VERSION ""

NS_ :

BS_:

BU_: Main_Module Torque_Vector Driveline Precharge Dashboard BMS_LV TESTER Precharge BMS1 TEST_NODE TEST_NODE_2 DAQ

BO_ 2214592576 driver_request: 4 Main_Module
 SG_ regen : 16|16@1+ (1,0) [0|0] "" Vector__XXX
 SG_ accel : 0|16@1+ (1,0) [0|0] "" Vector__XXX

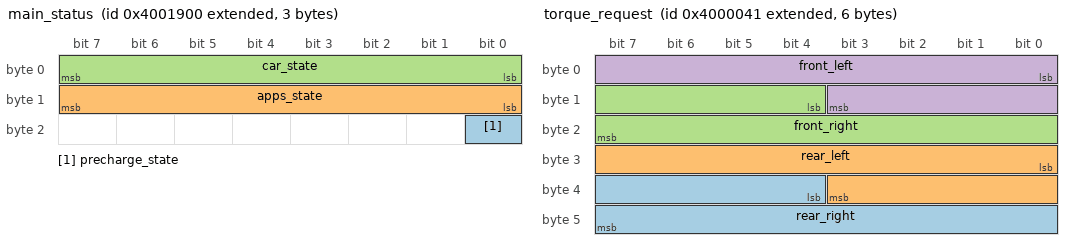
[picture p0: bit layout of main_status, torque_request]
BO_ 2214598912 main_status: 3 Main_Module
 SG_ precharge_state : 16|1@1+ (1,0) [0|0] "" Vector__XXX
 SG_ apps_state : 8|8@1+ (1,0) [0|0] "" Vector__XXX
 SG_ car_state : 0|8@1+ (1,0) [0|0] "" Vector__XXX

BO_ 2214592577 torque_request: 6 Torque_Vector
 SG_ rear_right : 36|12@1+ (1,0) [0|0] "" Vector__XXX
 SG_ rear_left : 24|12@1+ (1,0) [0|0] "" Vector__XXX
 SG_ front_right : 12|12@1+ (1,0) [0|0] "" Vector__XXX
 SG_ front_left : 0|12@1+ (1,0) [0|0] "" Vector__XXX

BO_ 2147490049 bitstream_flash_status: 1 Torque_Vector
 SG_ flash_timeout_rx : 1|1@1+ (1,0) [0|0] "" Vector__XXX
 SG_ flash_success : 0|1@1+ (1,0) [0|0] "" Vector__XXX

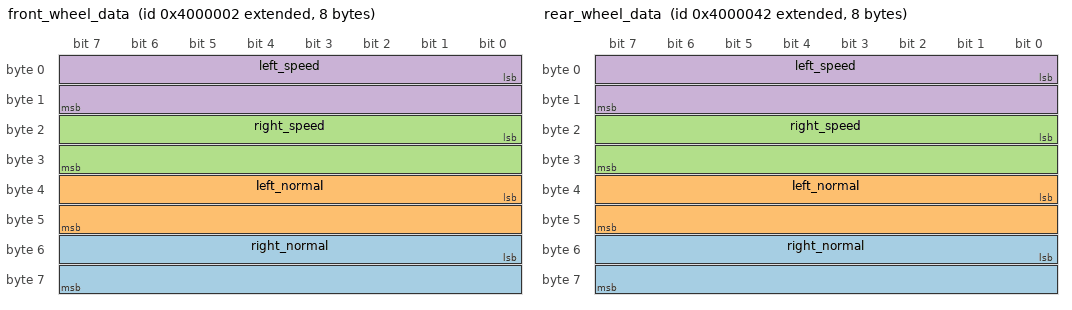
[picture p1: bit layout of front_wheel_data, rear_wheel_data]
BO_ 2214592514 front_wheel_data: 8 Driveline
 SG_ right_normal : 48|16@1+ (1,0) [0|0] "" Vector__XXX
 SG_ left_normal : 32|16@1+ (1,0) [0|0] "" Vector__XXX
 SG_ right_speed : 16|16@1+ (1,0) [0|0] "" Vector__XXX
 SG_ left_speed : 0|16@1+ (1,0) [0|0] "" Vector__XXX

BO_ 2214592578 rear_wheel_data: 8 Driveline
 SG_ right_normal : 48|16@1+ (1,0) [0|0] "" Vector__XXX
 SG_ left_normal : 32|16@1+ (1,0) [0|0] "" Vector__XXX
 SG_ right_speed : 16|16@1+ (1,0) [0|0] "" Vector__XXX
 SG_ left_speed : 0|16@1+ (1,0) [0|0] "" Vector__XXX

BO_ 2348810882 front_motor_currents: 4 Driveline
 SG_ right : 16|16@1+ (1,0) [0|0] "" Vector__XXX
 SG_ left : 0|16@1+ (1,0) [0|0] "" Vector__XXX

BO_ 2348810946 rear_motor_currents: 4 Driveline
 SG_ right : 16|16@1+ (1,0) [0|0] "" Vector__XXX
 SG_ left : 0|16@1+ (1,0) [0|0] "" Vector__XXX

BO_ 2281734148 test_precharge_msg: 1 Precharge
 SG_ test_precharge_sig : 0|8@1+ (1,0) [0|0] "" Vector__XXX

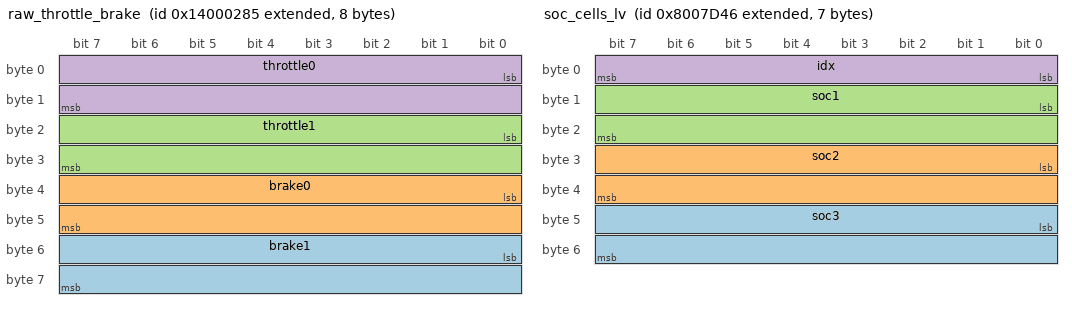
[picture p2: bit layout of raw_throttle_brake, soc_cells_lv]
BO_ 2483028613 raw_throttle_brake: 8 Dashboard
 SG_ brake1 : 48|16@1+ (1,0) [0|0] "" Vector__XXX
 SG_ brake0 : 32|16@1+ (1,0) [0|0] "" Vector__XXX
 SG_ throttle1 : 16|16@1+ (1,0) [0|0] "" Vector__XXX
 SG_ throttle0 : 0|16@1+ (1,0) [0|0] "" Vector__XXX

BO_ 2214592517 start_button: 1 Dashboard
 SG_ start : 0|1@1+ (1,0) [0|0] "" Vector__XXX

BO_ 2281733446 soc_cells_lv: 7 BMS_LV
 SG_ soc3 : 40|16@1+ (1,0) [0|0] "" Vector__XXX
 SG_ soc2 : 24|16@1+ (1,0) [0|0] "" Vector__XXX
 SG_ soc1 : 8|16@1+ (1,0) [0|0] "" Vector__XXX
 SG_ idx : 0|8@1+ (1,0) [0|0] "" Vector__XXX

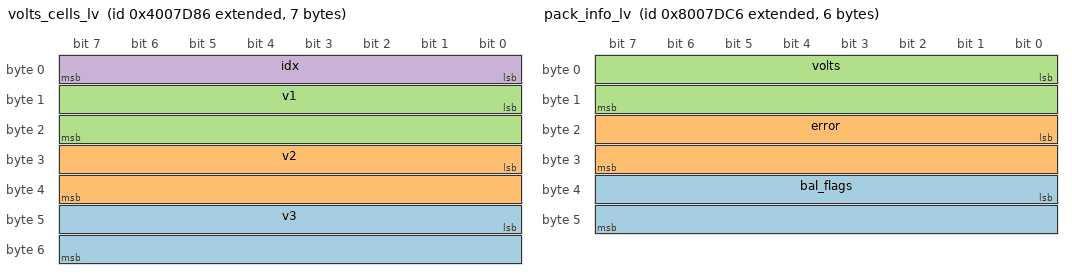
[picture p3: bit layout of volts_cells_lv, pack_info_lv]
BO_ 2214624646 volts_cells_lv: 7 BMS_LV
 SG_ v3 : 40|16@1+ (1,0) [0|0] "" Vector__XXX
 SG_ v2 : 24|16@1+ (1,0) [0|0] "" Vector__XXX
 SG_ v1 : 8|16@1+ (1,0) [0|0] "" Vector__XXX
 SG_ idx : 0|8@1+ (1,0) [0|0] "" Vector__XXX

BO_ 2281733574 pack_info_lv: 6 BMS_LV
 SG_ bal_flags : 32|16@1+ (1,0) [0|0] "" Vector__XXX
 SG_ error : 16|16@1+ (1,0) [0|0] "" Vector__XXX
 SG_ volts : 0|16@1+ (1,0) [0|0] "" Vector__XXX

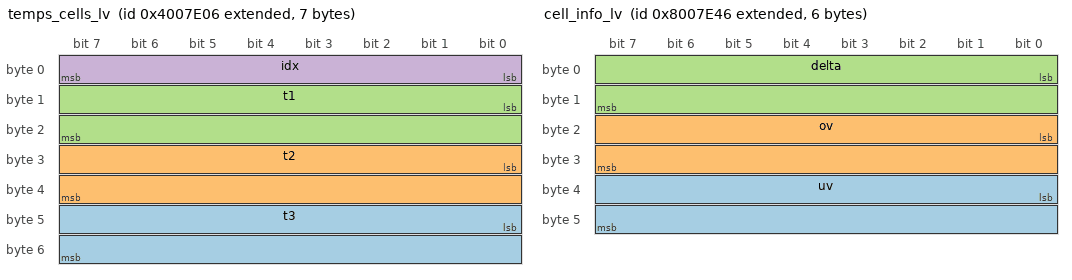
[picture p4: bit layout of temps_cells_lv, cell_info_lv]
BO_ 2214624774 temps_cells_lv: 7 BMS_LV
 SG_ t3 : 40|16@1+ (1,0) [0|0] "" Vector__XXX
 SG_ t2 : 24|16@1+ (1,0) [0|0] "" Vector__XXX
 SG_ t1 : 8|16@1+ (1,0) [0|0] "" Vector__XXX
 SG_ idx : 0|8@1+ (1,0) [0|0] "" Vector__XXX

BO_ 2281733702 cell_info_lv: 6 BMS_LV
 SG_ uv : 32|16@1+ (1,0) [0|0] "" Vector__XXX
 SG_ ov : 16|16@1+ (1,0) [0|0] "" Vector__XXX
 SG_ delta : 0|16@1+ (1,0) [0|0] "" Vector__XXX

BO_ 2214624902 power_lim_lv: 4 BMS_LV
 SG_ chg_lim : 16|16@1+ (1,0) [0|0] "" Vector__XXX
 SG_ disch_lim : 0|16@1+ (1,0) [0|0] "" Vector__XXX

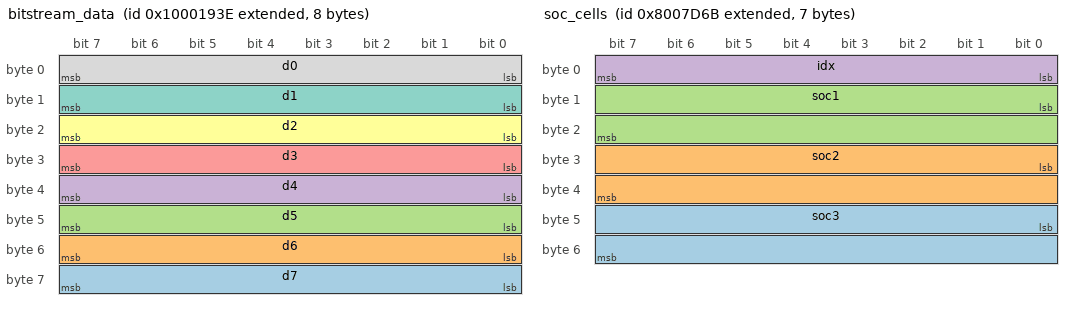
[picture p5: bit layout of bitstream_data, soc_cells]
BO_ 2415925566 bitstream_data: 8 TESTER
 SG_ d7 : 56|8@1+ (1,0) [0|0] "" Vector__XXX
 SG_ d6 : 48|8@1+ (1,0) [0|0] "" Vector__XXX
 SG_ d5 : 40|8@1+ (1,0) [0|0] "" Vector__XXX
 SG_ d4 : 32|8@1+ (1,0) [0|0] "" Vector__XXX
 SG_ d3 : 24|8@1+ (1,0) [0|0] "" Vector__XXX
 SG_ d2 : 16|8@1+ (1,0) [0|0] "" Vector__XXX
 SG_ d1 : 8|8@1+ (1,0) [0|0] "" Vector__XXX
 SG_ d0 : 0|8@1+ (1,0) [0|0] "" Vector__XXX

BO_ 2415925630 bitstream_request: 5 TESTER
 SG_ download_size : 1|32@1+ (1,0) [0|0] "" Vector__XXX
 SG_ download_request : 0|1@1+ (1,0) [0|0] "" Vector__XXX

BO_ 2281733418 heat_req: 3 Precharge
 SG_ time : 1|16@1+ (1,0) [0|0] "" Vector__XXX
 SG_ toggle : 0|1@1+ (1,0) [0|0] "" Vector__XXX

BO_ 2214624618 pack_curr: 2 Precharge
 SG_ current : 0|16@1- (1,0) [0|0] "" Vector__XXX

BO_ 2281733483 soc_cells: 7 BMS1
 SG_ soc3 : 40|16@1+ (1,0) [0|0] "" Vector__XXX
 SG_ soc2 : 24|16@1+ (1,0) [0|0] "" Vector__XXX
 SG_ soc1 : 8|16@1+ (1,0) [0|0] "" Vector__XXX
 SG_ idx : 0|8@1+ (1,0) [0|0] "" Vector__XXX

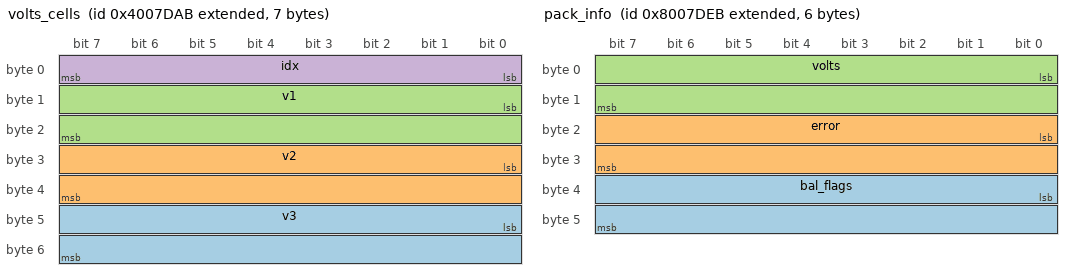
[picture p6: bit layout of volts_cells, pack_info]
BO_ 2214624683 volts_cells: 7 BMS1
 SG_ v3 : 40|16@1+ (1,0) [0|0] "" Vector__XXX
 SG_ v2 : 24|16@1+ (1,0) [0|0] "" Vector__XXX
 SG_ v1 : 8|16@1+ (1,0) [0|0] "" Vector__XXX
 SG_ idx : 0|8@1+ (1,0) [0|0] "" Vector__XXX

BO_ 2281733611 pack_info: 6 BMS1
 SG_ bal_flags : 32|16@1+ (1,0) [0|0] "" Vector__XXX
 SG_ error : 16|16@1+ (1,0) [0|0] "" Vector__XXX
 SG_ volts : 0|16@1+ (1,0) [0|0] "" Vector__XXX

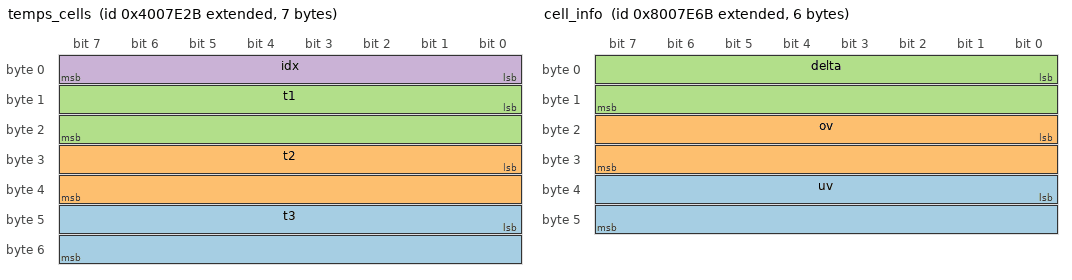
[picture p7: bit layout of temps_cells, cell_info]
BO_ 2214624811 temps_cells: 7 BMS1
 SG_ t3 : 40|16@1+ (1,0) [0|0] "" Vector__XXX
 SG_ t2 : 24|16@1+ (1,0) [0|0] "" Vector__XXX
 SG_ t1 : 8|16@1+ (1,0) [0|0] "" Vector__XXX
 SG_ idx : 0|8@1+ (1,0) [0|0] "" Vector__XXX

BO_ 2281733739 cell_info: 6 BMS1
 SG_ uv : 32|16@1+ (1,0) [0|0] "" Vector__XXX
 SG_ ov : 16|16@1+ (1,0) [0|0] "" Vector__XXX
 SG_ delta : 0|16@1+ (1,0) [0|0] "" Vector__XXX

BO_ 2214624939 power_lim: 4 BMS1
 SG_ chg_lim : 16|16@1+ (1,0) [0|0] "" Vector__XXX
 SG_ disch_lim : 0|16@1+ (1,0) [0|0] "" Vector__XXX

BO_ 2483028095 test_msg: 2 TEST_NODE
 SG_ test_sig : 0|16@1- (1,0) [0|0] "" Vector__XXX

BO_ 2483028159 test_msg2: 2 TEST_NODE
 SG_ test_sig2 : 0|16@1+ (1,0) [0|0] "" Vector__XXX

BO_ 2483028223 test_msg3: 2 TEST_NODE
 SG_ test_sig3 : 0|16@1+ (1,0) [0|0] "" Vector__XXX

BO_ 2483028287 test_msg4: 2 TEST_NODE
 SG_ test_sig4 : 0|16@1+ (1,0) [0|0] "" Vector__XXX

BO_ 2483028351 test_msg5: 2 TEST_NODE
 SG_ test_sig5 : 0|16@1+ (1,0) [0|0] "" Vector__XXX

BO_ 2348810751 wheel_speeds: 8 TEST_NODE
 SG_ right_speed : 32|32@1- (1,0) [0|0] "kph" Vector__XXX
 SG_ left_speed : 0|32@1- (1,0) [0|0] "kph" Vector__XXX

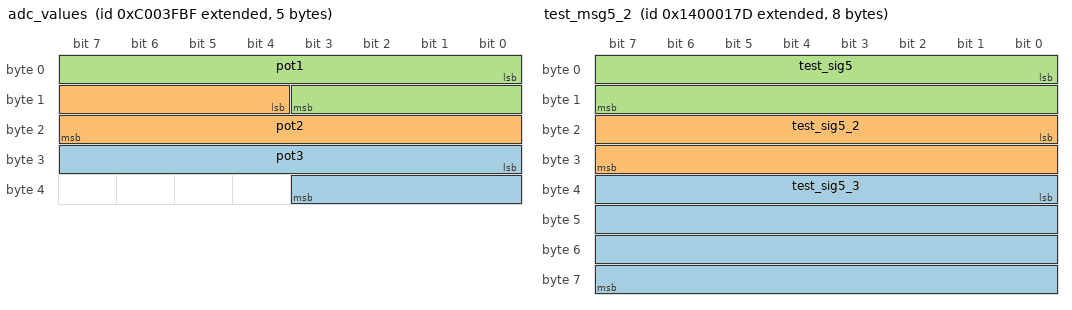
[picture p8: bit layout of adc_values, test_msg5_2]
BO_ 2348826559 adc_values: 5 TEST_NODE
 SG_ pot3 : 24|12@1+ (1,0) [0|0] "" Vector__XXX
 SG_ pot2 : 12|12@1+ (1,0) [0|0] "" Vector__XXX
 SG_ pot1 : 0|12@1+ (1,0) [0|0] "" Vector__XXX

BO_ 2550136831 daq_response_TEST_NODE: 8 TEST_NODE
 SG_ daq_response : 0|64@1+ (1,0) [0|0] "" Vector__XXX

BO_ 2483028093 test_msg_2: 2 TEST_NODE_2
 SG_ test_sig : 0|16@1+ (1,0) [0|0] "" Vector__XXX

BO_ 2483028157 test_msg2_2: 2 TEST_NODE_2
 SG_ test_sig2 : 0|16@1+ (1,0) [0|0] "" Vector__XXX

BO_ 2483028221 test_msg3_2: 2 TEST_NODE_2
 SG_ test_sig3 : 0|16@1+ (1,0) [0|0] "" Vector__XXX

BO_ 2483028285 test_msg4_2: 2 TEST_NODE_2
 SG_ test_sig4 : 0|16@1+ (1,0) [0|0] "" Vector__XXX

BO_ 2483028349 test_msg5_2: 8 TEST_NODE_2
 SG_ test_sig5_3 : 32|32@1- (1,0) [0|0] "" Vector__XXX
 SG_ test_sig5_2 : 16|16@1- (1,0) [0|0] "" Vector__XXX
 SG_ test_sig5 : 0|16@1+ (1,0) [0|0] "" Vector__XXX

BO_ 2550136829 daq_response_TEST_NODE_2: 8 TEST_NODE_2
 SG_ daq_response : 0|64@1+ (1,0) [0|0] "" Vector__XXX

BO_ 2483032050 daq_command_TEST_NODE: 8 DAQ
 SG_ daq_command : 0|64@1+ (1,0) [0|0] "" Vector__XXX

BO_ 2483031922 daq_command_TEST_NODE_2: 8 DAQ
 SG_ daq_command : 0|64@1+ (1,0) [0|0] "" Vector__XXX

CM_ BO_ 2214592576 "Driver throttle/regeneration request";
CM_ SG_ 2214592576 regen "regen request. 0-4096";
CM_ SG_ 2214592576 accel "accel request. 0-4096";
CM_ BO_ 2214598912 "Status message for main module";
CM_ SG_ 2214598912 precharge_state "Precharge complete state";
CM_ SG_ 2214598912 apps_state "Accelerator plausibility state";
CM_ SG_ 2214598912 car_state "Main car state";
CM_ BO_ 2214592577 "Torque request for all motors.";
CM_ SG_ 2214592577 rear_right "torque request. 0-4096";
CM_ SG_ 2214592577 rear_left "torque request. 0-4096";
CM_ SG_ 2214592577 front_right "torque request. 0-4096";
CM_ SG_ 2214592577 front_left "torque request. 0-4096";
CM_ BO_ 2147490049 "Status message for bitstream flashing";
CM_ SG_ 2147490049 flash_timeout_rx "Timeout from CAN rx";
CM_ SG_ 2147490049 flash_success "Done flashing bitstream";
CM_ BO_ 2214592514 "Wheel data for the rear tires";
CM_ BO_ 2214592578 "Wheel data for the rear tires";
CM_ BO_ 2348810882 "DC Current of the motor controllers";
CM_ BO_ 2348810946 "DC Current of the motor controllers";
CM_ BO_ 2281734148 "test precharge desc";
CM_ BO_ 2483028613 "throttle_brake desc";
CM_ BO_ 2214592517 "Car start button pressed";
CM_ BO_ 2281733446 "Estimated soc";
CM_ SG_ 2281733446 soc3 "Cell 2 in % * 100";
CM_ SG_ 2281733446 soc2 "Cell 1 in % * 100";
CM_ SG_ 2281733446 soc1 "Cell 0 in % * 100";
CM_ SG_ 2281733446 idx "Index of each set";
CM_ BO_ 2214624646 "Measured cell voltages";
CM_ SG_ 2214624646 v3 "Cell 2 in V * 10000";
CM_ SG_ 2214624646 v2 "Cell 1 in V * 10000";
CM_ SG_ 2214624646 v1 "Cell 0 in V * 10000";
CM_ SG_ 2214624646 idx "Index of each set";
CM_ BO_ 2281733574 "Pack information";
CM_ SG_ 2281733574 bal_flags "Balance flags. 1 for on";
CM_ SG_ 2281733574 error "Error flags (non-zero is fault)";
CM_ SG_ 2281733574 volts "Pack voltage in V * 10000";
CM_ BO_ 2214624774 "Measured cell temperatures";
CM_ SG_ 2214624774 t3 "Cell 2 in deg C * 10000";
CM_ SG_ 2214624774 t2 "Cell 1 in deg C * 10000";
CM_ SG_ 2214624774 t1 "Cell 0 in deg C * 10000";
CM_ SG_ 2214624774 idx "Index of each set";
CM_ BO_ 2281733702 "Cell information";
CM_ SG_ 2281733702 uv "Under-voltage flags. 1 for fault";
CM_ SG_ 2281733702 ov "Over-voltage flags. 1 for fault";
CM_ SG_ 2281733702 delta "Max cell delta in V * 10000";
CM_ BO_ 2214624902 "Power limits";
CM_ SG_ 2214624902 chg_lim "Charge limit in W";
CM_ SG_ 2214624902 disch_lim "Discharge limit in W";
CM_ BO_ 2415925566 "Bitstream download command";
CM_ SG_ 2415925566 d7 "Bitstream data word 7";
CM_ SG_ 2415925566 d6 "Bitstream data word 6";
CM_ SG_ 2415925566 d5 "Bitstream data word 5";
CM_ SG_ 2415925566 d4 "Bitstream data word 4";
CM_ SG_ 2415925566 d3 "Bitstream data word 3";
CM_ SG_ 2415925566 d2 "Bitstream data word 2";
CM_ SG_ 2415925566 d1 "Bitstream data word 1";
CM_ SG_ 2415925566 d0 "Bitstream data word 0";
CM_ BO_ 2415925630 "Bitstream state command";
CM_ SG_ 2415925630 download_size "size for expected bitstream download (bytes)";
CM_ SG_ 2415925630 download_request "Request to download new bitstream";
CM_ BO_ 2281733418 "Starts BMS pre-heat for set time";
CM_ SG_ 2281733418 time "Set runtime in ms";
CM_ SG_ 2281733418 toggle "1 for start, 0 for stop";
CM_ BO_ 2214624618 "Pack current";
CM_ SG_ 2214624618 current "Pack current";
CM_ BO_ 2281733483 "Estimated soc";
CM_ SG_ 2281733483 soc3 "Cell 2 in % * 100";
CM_ SG_ 2281733483 soc2 "Cell 1 in % * 100";
CM_ SG_ 2281733483 soc1 "Cell 0 in % * 100";
CM_ SG_ 2281733483 idx "Index of each set";
CM_ BO_ 2214624683 "Measured cell voltages";
CM_ SG_ 2214624683 v3 "Cell 2 in V * 10000";
CM_ SG_ 2214624683 v2 "Cell 1 in V * 10000";
CM_ SG_ 2214624683 v1 "Cell 0 in V * 10000";
CM_ SG_ 2214624683 idx "Index of each set";
CM_ BO_ 2281733611 "Pack information";
CM_ SG_ 2281733611 bal_flags "Balance flags. 1 for on";
CM_ SG_ 2281733611 error "Error flags (non-zero is fault)";
CM_ SG_ 2281733611 volts "Pack voltage in V * 10000";
CM_ BO_ 2214624811 "Measured cell temperatures";
CM_ SG_ 2214624811 t3 "Cell 2 in deg C * 10000";
CM_ SG_ 2214624811 t2 "Cell 1 in deg C * 10000";
CM_ SG_ 2214624811 t1 "Cell 0 in deg C * 10000";
CM_ SG_ 2214624811 idx "Index of each set";
CM_ BO_ 2281733739 "Cell information";
CM_ SG_ 2281733739 uv "Under-voltage flags. 1 for fault";
CM_ SG_ 2281733739 ov "Over-voltage flags. 1 for fault";
CM_ SG_ 2281733739 delta "Max cell delta in V * 10000";
CM_ BO_ 2214624939 "Power limits";
CM_ SG_ 2214624939 chg_lim "Charge limit in W";
CM_ SG_ 2214624939 disch_lim "Discharge limit in W";
CM_ BO_ 2483028095 "test_msg desc";
CM_ BO_ 2483028159 "test_msg2 desc";
CM_ BO_ 2483028223 "test_msg2 desc";
CM_ BO_ 2483028287 "test_msg4 desc";
CM_ BO_ 2483028351 "test_msg5 desc";
CM_ BO_ 2348810751 "wheel speeds";
CM_ BO_ 2348826559 "adc potentiometer readings";
CM_ BO_ 2550136831 "daq response from node TEST_NODE";
CM_ BO_ 2483028093 "test_msg desc";
CM_ BO_ 2483028157 "test_msg2 desc";
CM_ BO_ 2483028221 "test_msg2 desc";
CM_ BO_ 2483028285 "test_msg4 desc";
CM_ BO_ 2483028349 "test_msg5 desc";
CM_ BO_ 2550136829 "daq response from node TEST_NODE_2";
CM_ BO_ 2483032050 "daq command for node TEST_NODE";
CM_ BO_ 2483031922 "daq command for node TEST_NODE_2";

SIG_VALTYPE_ 2348810751 left_speed : 1;
SIG_VALTYPE_ 2348810751 right_speed : 1;
SIG_VALTYPE_ 2483028349 test_sig5_3 : 1;
